# RS14100 register map
File version: 1.0
CPU: CM4 r0p1, little endian, MPU, FPU, 4 interrupt priority bits
Registers are 32-bit, read-write, reset 0x0 unless marked. A register's access mark holds for its fields unless they carry their own. Offsets are from the block's base; [hi:lo] are bit positions; {n}, {i} and the like mark numbered series.

## CAN0 — The DCAN is a standalone CAN (Controller Area Network) controller widely used in automotive and industrial applications.
Base 0x45070000
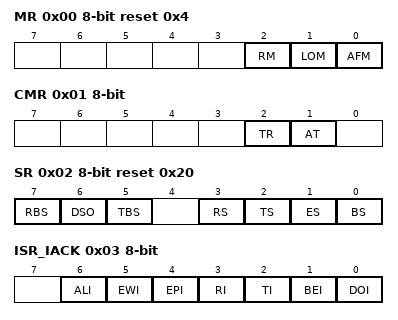
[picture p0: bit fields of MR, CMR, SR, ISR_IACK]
0x00 MR 8-bit reset 0x4 — Mode Register
  [2] RM — Reset Mode
    0=Disable (Normal mode or Listen only mode depending on LOM value); 1=Enable (DCAN works in reset mode)
  [1] LOM — Listen Only Mode
    0=Disable (Normal mode is set by writing 0 to LOM and 0to RM while in reset mode); 1=Enable (Listen only mode is set by writing 1 to LOM bit and 0 to RM bit while in reset mode)
  [0] AFM — hardware acceptance filter scheme
    0=Disable (dual filter is used); 1=Enable (single filter is used)
0x01 CMR 8-bit — Command Register
  [2] TR wo — Transmit Request
    0=Disable (NONE); 1=Enable (initiates frame transmission by Bit Stream Processor)
  [1] AT wo — Abort Transmission
0x02 SR 8-bit ro reset 0x20 — Status register
  [7] RBS — Data Overrun Status
    0=Disable (no messages are in FIFO); 1=Enable (at least one message is in FIFO)
  [6] DSO — Data Overrun Status
    0=Disable (no overrun occurred since last clear data overrun command.); 1=Enable (RX FIFO encounters overrun)
  [5] TBS — Transmit Buffer Status
    0=Disable (transmit buffer is locked for CPU (ie. message is being transmitted or transmission pending).); 1=Enable (transmit buffer is released for CPU (ie. CPU may write new message into TX buffer).)
  [3] RS — Receive Status
    0=Disable (NONE); 1=Enable (DCAN core is receiving a message.)
  [2] TS — Transmit Status
    0=Disable (NONE); 1=Enable (DCAN core is transmitting a message)
  [1] ES — Error Status
    0=Disable (NONE); 1=Enable (At least one of CAN error counters reached error warning limit (96).)
  [0] BS — Bus Off Status
    0=Disable (frame reception and transmission is possible); 1=Enable (node is in bus off state and cannot transmit and receive frames)
0x03 ISR_IACK 8-bit — Interrupt Status/Acknowledge Register
  [6] ALI — Arbitration Lost Interrupt
    0=Disable (Write 1 to ALI clears this interrupt); 1=Enable (ALI (Arbitration Lost Interrupt) is activated when DCAN core lost arbitration during transmission of its own message and became a receiver.)
  [5] EWI — Error Warning Interrupt
    0=Disable (Write 1 to EWI to clear interrupt); 1=Enable (CAN bus controller reached or exit error passive level (i.e. on state change active-to-passive or passive-to-active).)
  [4] EPI — Error Passive Interrupt
    0=Disable (Write 1 to EPI clears the Error Passive Interrupt); 1=Enable (CAN bus controller reached or exit error passive level (i.e. on state change active-to-passive or passive-to-active).)
  [3] RI — Receive Interrupt
    0=Disable (CPU must write RI bit with 1 (message read acknowledge), to decrement RX message counter (RMC)); 1=Enable (there is at least one message in the receive FIFO.)
  [2] TI — Transmission Interrupt
    0=Disable (TI bit must be cleared by CPU by writing 1 to it to reset write pointer to TX RAM before next frame data will be written.); 1=Enable (bit is set high after successful transmission)
  [1] BEI — Bus Error Interrupt
    0=Disable (BEI interrupt write 1 to this bit.); 1=Enable (DCAN encounters bus error while transmitting or receiving message)
  [0] DOI — Data Overrun Interrupt
    0=Disable (DOI interrupt write this bit with 1.); 1=Enable (receive FIFO overrun occurred)
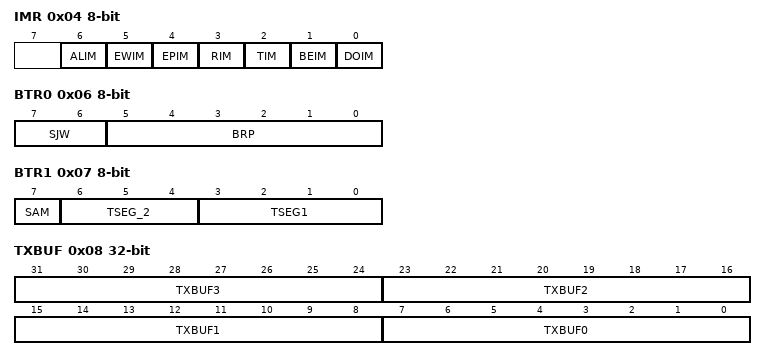
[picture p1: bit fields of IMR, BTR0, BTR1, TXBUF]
0x04 IMR 8-bit — Interrupt Mask register.Setting appropriate bit in IMR register enables interrupt assigned to it, clearing disables this interrupt
  [6] ALIM — mask for ALI interrupt
  [5] EWIM — mask for EWI interrupt
  [4] EPIM — mask for EPI interrupt
  [3] RIM — mask for RI interrupt
  [2] TIM — mask for TI interrupt
  [1] BEIM — mask for BEI interrupt
  [0] DOIM — mask for DOI interrupt
0x05 RMC 8-bit ro (reset mask 0x3) — Receive Message Counter
  [4:0] RMC — number of stored message frames
0x06 BTR0 8-bit — BUS TIMING REGISTER 0
  [7:6] SJW — Synchronization Jump Width
  [5:0] BRP — Baud Rate Pre scaler
0x07 BTR1 8-bit — BUS TIMING REGISTER 1.define the length of bit period, location of the sample point and number of samples to be taken at each sample point
  [7] SAM — Number of bus level samples
    0=Disable (bus level is sampled once); 1=Enable (bus level is sampled three times)
  [6:4] TSEG_2 — Number of clock cycles per Time Segment 1
  [3:0] TSEG1 — Number of clock cycles per Time Segment 1
0x08 TXBUF wo — TRANSMIT BUFFER REGISTER
  [8n+7:8n] TXBUF{n} (n=0..3) — Transmit Buffer Register is used to write CAN frame destined to send over CAN network.
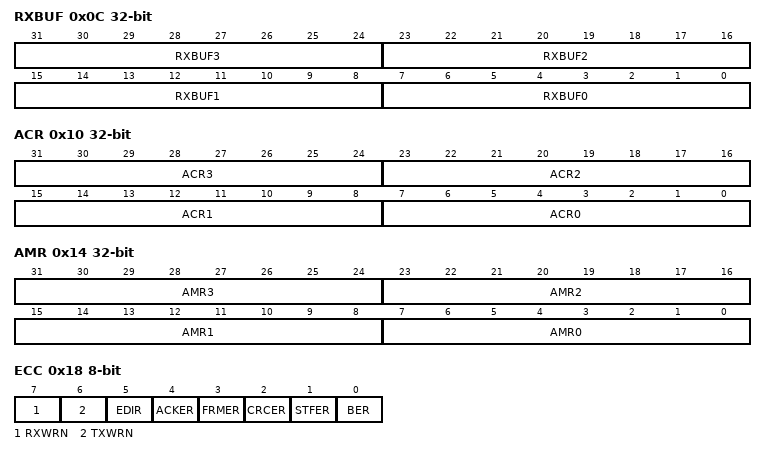
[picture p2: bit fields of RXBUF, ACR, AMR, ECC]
0x0C RXBUF ro — RECEIVE BUFFER REGISTER
  [8n+7:8n] RXBUF{n} (n=0..3) — Receive Buffer Register is used to read CAN frames received by the DCAN core from CAN network
0x10 ACR — ACCEPTANCE CODE REGISTER
  [8n+7:8n] ACR{n} (n=0..3) — The acceptance code registers contains bit patterns of messages to be received
0x14 AMR — ACCEPTANCE MASK REGISTER
  [31:24] AMR3 — acceptance mask registers defines which bit positions will be compared and which ones are do not care. Setting certain AMR bit define corresponding bit in ACR as do not care.
  [23:16] AMR2 — acceptance mask registers defines which bit positions will be compared and which ones are do not care. Setting certain AMR bit define corresponding bit in ACR as do not care.
  [15:8] AMR1 — acceptance mask registers defines which bit positions will be compared and which ones are do not care. Setting certain AMR bit define corresponding bit in ACR as do not care.
  [7:0] AMR0 — Acceptance mask registers defines which bit positions will be compared and which ones are do not care. Setting certain AMR bit define corresponding bit in ACR as do not care.
0x18 ECC 8-bit ro — ERROR CODE CAPTURE REGISTER
  [7] RXWRN — set when RXERR counter is greater than or equal to 96
  [6] TXWRN — set when TXERR counter is greater than or equal to 96
  [5] EDIR — direction of transfer while error occurred
    0=Disable (Transmission); 1=Enable (Reception)
  [4] ACKER — Acknowledgement error occurred
  [3] FRMER — Frame error occurred
  [2] CRCER — CRC error occurred
  [1] STFER — stuff error occurred
  [0] BER — Bit Error occurred
0x19 RXERR 8-bit ro — RECEIVE ERROR COUNTER REGISTER
  [7:0] RXERR — The RXERR register reflects current value of the receive error counter
0x1A TXERR 8-bit ro — RECEIVE ERROR COUNTER REGISTER
  [7:0] TXERR — The TXERR register reflects current value of the transmit error counter
0x1B ALC 8-bit ro — ARBITRATION LOST CODE CAPTURE REGISTER
  [4:0] ALC — Arbitration Lost Capture
